# STM32H7B3xxQ register map
File version: 1.0
Registers are 32-bit, read-write, reset 0x0 unless marked. A register's access mark holds for its fields unless they carry their own. Offsets are from the block's base; [hi:lo] are bit positions; {n}, {i} and the like mark numbered series.

## PWR — Power Control
Base 0x58024800
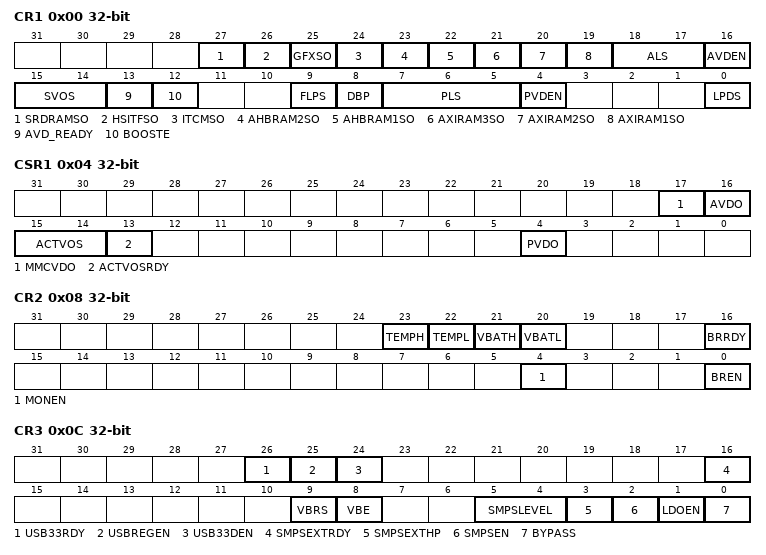
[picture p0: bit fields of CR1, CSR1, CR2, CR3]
0x00 CR1 — PWR power control register 1
  [27] SRDRAMSO — SmartRun Domain AHB Memory Shut-Off in DStop/DStop2 Low-Power Mode
  [26] HSITFSO — High-Speed Interfaces USB and FDCAN Memories Shut-off in DStop/DStop2 Mode
  [25] GFXSO — GFXMMU and JPEG Memories Shut-Off in DStop/DStop2 Mode
  [24] ITCMSO — Instruction TCM and ETM Memories Shut-Off in DStop/DStop2 Mode
  [23] AHBRAM2SO — AHB RAM2 Shut-Off in DStop/DStop2 Mode
  [22] AHBRAM1SO — AHB RAM1 Shut-Off in DStop/DStop2 Mode
  [21] AXIRAM3SO — AXI RAM3 Shut-Off in DStop/DStop2 Mode
  [20] AXIRAM2SO — AXI RAM2 Shut-Off in DStop/DStop2 Mode
  [19] AXIRAM1SO — AXI RAM1 Shut-Off in DStop/DStop2 Mode
  [18:17] ALS — Analog Voltage Detector level selection
    0=AVDLEVEL_0 (Analog Voltage threshold detected by AVD 1.7 V); 1=AVDLEVEL_1 (Analog Voltage threshold detected by AVD 2.1 V); 2=AVDLEVEL_2 (Analog Voltage threshold detected by AVD 2.5 V); 3=AVDLEVEL_3 (Analog Voltage threshold detected by AVD 2.8 V)
  [16] AVDEN — Analog Voltage Detector Enable
  [15:14] SVOS — System STOP mode Voltage Scaling selection
    3=SCALE3 (Select voltage scale 3 when system enters STOP mode); 2=SCALE4 (Select voltage scale 4 when system enters STOP mode); 1=SCALE5 (Select voltage scale 5 when system enters STOP mode)
  [13] AVD_READY — Analog Voltage Ready
  [12] BOOSTE — Analog Switch VBoost control
  [9] FLPS — Flash low power mode in DSTOP
  [8] DBP — Disable Back-up domain Protection
  [7:5] PLS — Programmable Voltage Detector level selection
    0=PVDLEVEL_0 (Voltage threshold detected by PVD 1.95 V); 1=PVDLEVEL_1 (Voltage threshold detected by PVD 2.1 V); 2=PVDLEVEL_2 (Voltage threshold detected by PVD 2.25 V); 3=PVDLEVEL_3 (Voltage threshold detected by PVD 2.4 V); 4=PVDLEVEL_4 (Voltage threshold detected by PVD 2.55 V); 5=PVDLEVEL_5 (Voltage threshold detected by PVD 2.7 V); 6=PVDLEVEL_6 (Voltage threshold detected by PVD 2.85 V); 7=PVDLEVEL_7 (External voltage level on PVD_IN pin, compared to internal VREFINT level.)
  [4] PVDEN — Programmable Voltage detector enable
  [0] LPDS — Low Power Deepsleep with SVOS3
    0=MAIN (Voltage Regulator in main mode during deepsleep mode); 1=LOW_POWER (Voltage Regulator in low-power mode during deepsleep mode)
0x04 CSR1 — PWR power control status register 1
  [17] MMCVDO — voltage detector output on VDDMMC
  [16] AVDO — Analog Voltage Detect Output
  [15:14] ACTVOS — Current actual used VOS for VDD11 Voltage Scaling
  [13] ACTVOSRDY — Ready bit for current actual used VOS for VDD11 Voltage Scaling
  [4] PVDO — Programmable Voltage Detect Output
0x08 CR2 — PWR power control register 2
  [23] TEMPH — Monitored temperature level above high threshold
  [22] TEMPL — Monitored temperature level above low threshold
  [21] VBATH — Monitored VBAT level above high threshold
  [20] VBATL — Monitored VBAT level above low threshold
  [16] BRRDY — Backup regulator ready
  [4] MONEN — VBAT and temperature monitoring enable
  [0] BREN — Backup regulator enable
0x0C CR3 — PWR power control register 3
  [26] USB33RDY — USB supply ready
  [25] USBREGEN — USB regulator enable
  [24] USB33DEN — VDD33_USB voltage level detector enable
  [16] SMPSEXTRDY — SMPS External supply ready
  [9] VBRS — VBAT charging resistor selection
    0=CHARG_RESISTOR_5K (Charge the Battery through a 5 kO resistor); 1=CHARGRESISTOR_1_5K (Charge the Battery through a 1.5 kO resistor)
  [8] VBE — VBAT charging enable
  [5:4] SMPSLEVEL — SMPS output Voltage
  [3] SMPSEXTHP — SMPS forced ON and in High Power MR mode
  [2] SMPSEN — SMPS Enable
  [1] LDOEN — Low Drop Output regulator enable
  [0] BYPASS — Power Management Unit bypass
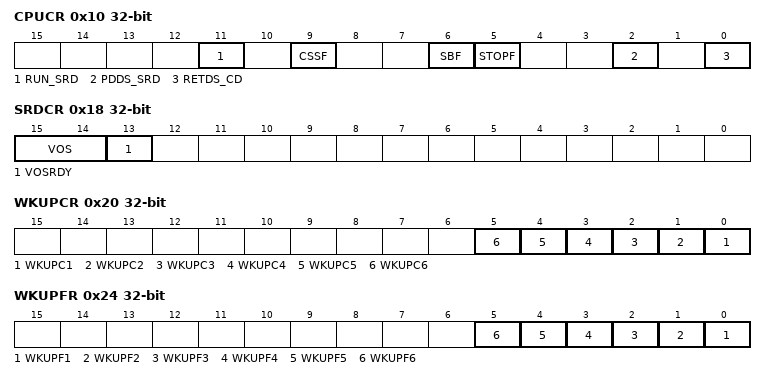
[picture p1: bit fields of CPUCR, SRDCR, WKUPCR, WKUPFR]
0x10 CPUCR — PWR CPU control register
  [11] RUN_SRD — Keep system SRD domain in RUN mode regardless of the CPU sub-systems modes
  [9] CSSF — Clear D1 domain CPU1 STANDBY, STOP and HOLD flags
  [6] SBF — System STANDBY Flag
  [5] STOPF — STOP Flag
  [2] PDDS_SRD — System SRD domain Power Down Deepsleep
    0=SRDSTOP (Enter SRD domain to Stop mode when the CPU enters deepsleep); 1=SRDSTANDBY (Enter SRD domain to Standby mode when the CPU enters deepsleep)
  [0] RETDS_CD — CD domain Power Down Deepsleep selection
    0=CDSTOP (Enter CD domain to Stop mode when the CPU enters deepsleep); 1=CDSTOP2 (Enter CD domain to Stop2 mode when the CPU enters deepsleep)
0x18 SRDCR — PWR SRD domain control register
  [15:14] VOS — Voltage Scaling selection according performance
  [13] VOSRDY — VOS Ready bit for VDD11 Voltage Scaling output selection
0x20 WKUPCR — PWR wakeup clear register
  [n-1] WKUPC{n} (n=1..6) — Clear Wakeup Pin Flag {n}
0x24 WKUPFR — PWR wakeup flag register
  [n-1] WKUPF{n} (n=1..6) — Wakeup Pin Flag {n}
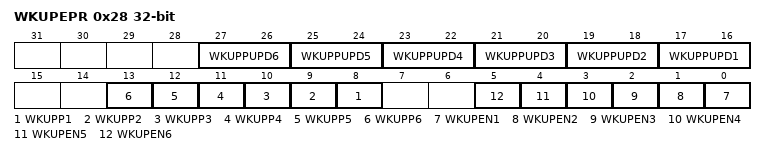
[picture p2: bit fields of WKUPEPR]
0x28 WKUPEPR — PWR wakeup enable and polarity register
  [2n+15:2n+14] WKUPPUPD{n} (n=1..6) — Wakeup Pin pull configuration for WKUP{n}
  [n+7] WKUPP{n} (n=1..6) — Wakeup Pin Polarity for WKUP{n}
  [n-1] WKUPEN{n} (n=1..6) — Enable Wakeup Pin WKUP{n}
